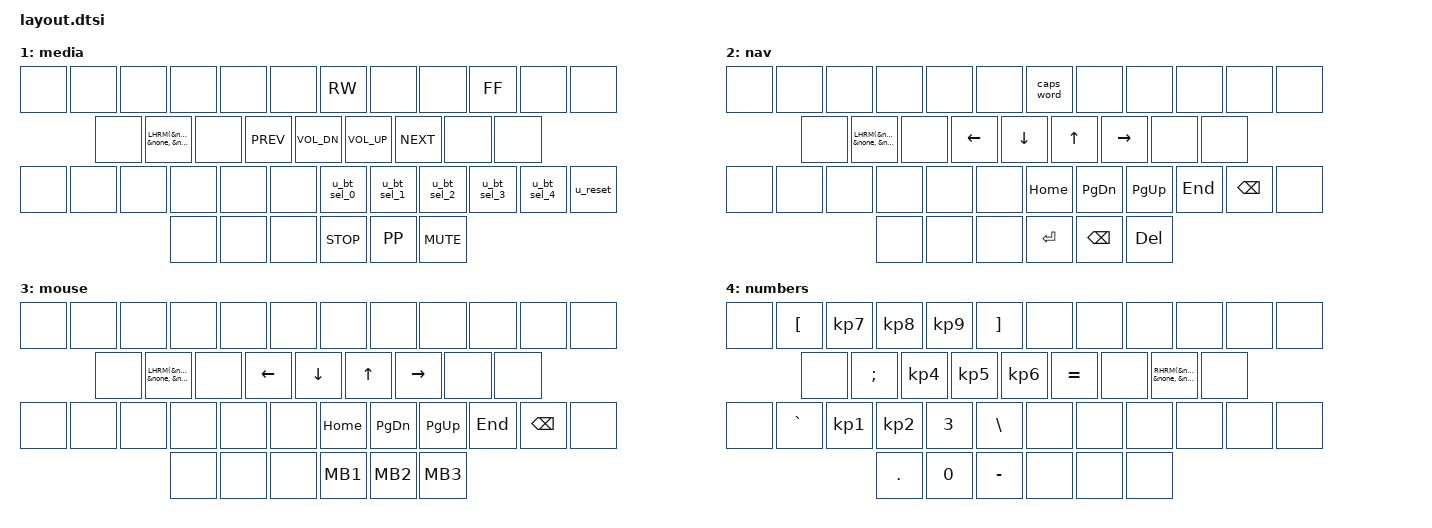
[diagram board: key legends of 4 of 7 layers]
// #include <behaviors.dtsi>
#include <dt-bindings/zmk/keys.h>
#include <dt-bindings/zmk/bt.h>
#include <dt-bindings/zmk/outputs.h>
#include <dt-bindings/zmk/ext_power.h>

#include "layout.h"

#include "mouse.dtsi"
#include "shift_functions.dtsi"

#define LHRM(k1, k2, k3, k4) &lhmr LGUI k1 &lhmr LALT k2 &lhmr LCTRL k3 &lhmr LSHIFT k4
#define RHRM(k1, k2, k3, k4) &rhmr RGUI k4 &rhmr RALT k3 &rhmr RCTRL k2 &rhmr RSHIFT k1

#define BASE 0
#define MEDIA 1
#define NAV 2
#define MOUSE 3
#define NUM 4
#define SYM 5
#define FUNC 6

&caps_word {
  continue-list = <UNDERSCORE MINUS>;
};

// #if defined(NICE_VIEW_SPI)
// &nice_view_spi {
//   cs-gpios = <NICE_VIEW_SPI>;
// };
// #endif

/
{
  keymap {
    compatible = "zmk,keymap";

    // behaviors {
    //   rhmr:
    //     rhmr {
    //       compatible = "zmk,behavior-hold-tap";
    //       bindings = <&kp>, <&kp>;
    //
    //       #binding-cells = < 2>;
    //       tapping-term-ms = <300>;
    //       quick-tap-ms = <250>;
    //       flavor = "tap-preferred";
    //       require-prior-idle-ms = <150>;
    //       hold-trigger-key-positions = <0 1 2 3 4 5 12 13 14 15 16 17 24 25 26 27 28 29 36 37 38 39 40 41>;
    //     };
    //
    //   lhmr:
    //     lhmr {
    //       compatible = "zmk,behavior-hold-tap";
    //       bindings = <&kp>, <&kp>;
    //
    //       #binding-cells = < 2>;
    //       tapping-term-ms = <300>;
    //       quick-tap-ms = <250>;
    //       flavor = "tap-preferred";
    //       require-prior-idle-ms = <150>;
    //       hold-trigger-key-positions = <6 7 8 9 10 11 18 19 20 21 22 23 30 31 32 33 34 35 36 37 38 39 40 41>;
    //     };
    // };

    base {
      // ╭──────────┬──────────┬──────────┬──────────┬───────────┬──────────╮       ╭──────────┬───────────┬──────────┬──────────┬──────────┬──────────╮
      // │          │  Q       │  W       │  E       │  R        │  T       │       │  Y       │  U        │  I       │  O       │  P       │          │
      // ├──────────┼──────────┼──────────┼──────────┼───────────┼──────────┤       ├──────────┼───────────┼──────────┼──────────┼──────────┼──────────┤
      // │          │  A       │  S       │  D       │  F        │  G       │       │  H       │  J        │  K       │  L       │  '       │          │
      // ├──────────┼──────────┼──────────┼──────────┼───────────┼──────────┤       ├──────────┼───────────┼──────────┼──────────┼──────────┼──────────┤
      // │          │  Z       │  X       │  C       │  V        │  B       │       │  N       │  M        │  ,       │  .       │  /       │          │
      // ╰──────────┴──────────┼──────────┴─────┬────┴────────┬──┴──────────┤       ├──────────┴──┬────────┴────┬─────┴───────┬──┴──────────┴──────────╯
      //                       │  ESC           │ SPACE       │ TAB         │       │  ENTER      │  BCKSPC     │  DELETE     │
      //                       ╰────────────────┴─────────────┴─────────────╯       ╰─────────────┴─────────────┴─────────────╯
      bindings = <&none &kp Q &kp W &kp E &kp R &kp T &kp Y &kp U &kp I &kp O &kp P &none

                  &none LHRM(A, S, D, F) &kp G &kp H RHRM(J, K, L, SINGLE_QUOTE) &none

                  &none &kp Z &kp X &kp C &kp V &kp B &kp N &kp M &kp COMMA &kp DOT &kp FSLH &none

                  &lt MEDIA ESC &lt NAV SPACE &lt MOUSE TAB &lt NUM RET &lt SYM BSPC &lt FUNC DEL>;
    };

    media {
      // ╭──────────┬──────────┬──────────┬──────────┬───────────┬──────────╮       ╭──────────┬───────────┬──────────┬──────────┬──────────┬──────────╮
      // │          │          │          │          │           │          │       │          │           │          │          │          │          │
      // ├──────────┼──────────┼──────────┼──────────┼───────────┼──────────┤       ├──────────┼───────────┼──────────┼──────────┼──────────┼──────────┤
      // │          │          │          │          │           │          │       │          │           │          │          │          │          │
      // ├──────────┼──────────┼──────────┼──────────┼───────────┼──────────┤       ├──────────┼───────────┼──────────┼──────────┼──────────┼──────────┤
      // │          │          │          │          │           │          │       │          │           │          │          │          │          │
      // ╰──────────┴──────────┼──────────┴─────┬────┴────────┬──┴──────────┤       ├──────────┴──┬────────┴────┬─────┴───────┬──┴──────────┴──────────╯
      //                       │                │             │             │       │             │             │             │
      //                       ╰────────────────┴─────────────┴─────────────╯       ╰─────────────┴─────────────┴─────────────╯
      bindings = <&none &none &none &none &none &none &kp C_RW &none &none &kp C_FF &none &none

                  &none LHRM(&none, &none, &none, &none) &none &kp K_PREV &kp C_VOL_DN &kp C_VOL_UP &kp K_NEXT &none &none

                  &none &none &none &none &none &none &u_bt_sel_0 &u_bt_sel_1 &u_bt_sel_2 &u_bt_sel_3 &u_bt_sel_4 &u_reset

                  &none &none &none &kp K_STOP &kp K_PP &kp C_MUTE>;
    };

    nav {
      // ╭──────────┬──────────┬──────────┬──────────┬───────────┬──────────╮       ╭──────────┬───────────┬──────────┬──────────┬──────────┬──────────╮
      // │          │          │          │          │           │          │       │ PScreen  │           │          │          │          │          │
      // ├──────────┼──────────┼──────────┼──────────┼───────────┼──────────┤       ├──────────┼───────────┼──────────┼──────────┼──────────┼──────────┤
      // │          │  GUI     │  ALT     │  CTRL    │  SHIFT    │          │       │ Left     │ Down      │ Up       │ Right    │          │          │
      // ├──────────┼──────────┼──────────┼──────────┼───────────┼──────────┤       ├──────────┼───────────┼──────────┼──────────┼──────────┼──────────┤
      // │          │          │          │          │           │          │       │ Home     │ Page down │ Page up  │ End      │          │          │
      // ╰──────────┴──────────┼──────────┴─────┬────┴────────┬──┴──────────┤       ├──────────┴──┬────────┴────┬─────┴───────┬──┴──────────┴──────────╯
      //                       │                │             │             │       │ ENTER       │ BCKSPC      │ DELETE      │
      //                       ╰────────────────┴─────────────┴─────────────╯       ╰─────────────┴─────────────┴─────────────╯
      bindings = <&none &none &none &none &none &none &caps_word &none &none &none &none &none

                  &none LHRM(&none, &none, &none, &none) &none &kp LEFT &kp DOWN &kp UP &kp RIGHT &none &none

                  &none &none &none &none &none &none &kp HOME &kp PG_DN &kp PG_UP &kp END &kp BSPC &none

                  &none &none &none &kp RET &kp BSPC &kp DEL>;
    };

    mouse {
      // ╭──────────┬──────────┬──────────┬──────────┬───────────┬──────────╮       ╭──────────┬───────────┬──────────┬──────────┬──────────┬──────────╮
      // │          │          │          │          │           │          │       │ PScreen  │           │          │          │          │          │
      // ├──────────┼──────────┼──────────┼──────────┼───────────┼──────────┤       ├──────────┼───────────┼──────────┼──────────┼──────────┼──────────┤
      // │          │  GUI     │  ALT     │  CTRL    │  SHIFT    │          │       │ M. Left  │ M. Down   │ M. Up    │ M. Right │          │          │
      // ├──────────┼──────────┼──────────┼──────────┼───────────┼──────────┤       ├──────────┼───────────┼──────────┼──────────┼──────────┼──────────┤
      // │          │          │          │          │           │          │       │ Home     │ Page down │ Page up  │ End      │          │          │
      // ╰──────────┴──────────┼──────────┴─────┬────┴────────┬──┴──────────┤       ├──────────┴──┬────────┴────┬─────┴───────┬──┴──────────┴──────────╯
      //                       │                │             │             │       │  ENTER      │  BCKSPC     │  DELETE     │
      //                       ╰────────────────┴─────────────┴─────────────╯       ╰─────────────┴─────────────┴─────────────╯
      bindings = <&none &none &none &none &none &none &none &none &none &none &none &none

                  // &none LHRM(&none, &none, &none, &none) &none U_MS_L U_MS_D U_MS_U U_MS_R &none &none
                  &none LHRM(&none, &none, &none, &none) &none &kp LEFT &kp DOWN &kp UP &kp RIGHT &none &none

                  &none &none &none &none &none &none &kp HOME &kp PG_DN &kp PG_UP &kp END &kp BSPC &none

                  &none &none &none &kp MB1 &kp MB2 &kp MB3>;
    };

    numbers {
      // ╭──────────┬──────────┬──────────┬──────────┬───────────┬──────────╮       ╭──────────┬───────────┬──────────┬──────────┬──────────┬──────────╮
      // │          │  [       │  7       │  8       │  9        │  ]       │       │          │           │          │          │          │          │
      // ├──────────┼──────────┼──────────┼──────────┼───────────┼──────────┤       ├──────────┼───────────┼──────────┼──────────┼──────────┼──────────┤
      // │          │  ;       │  4       │  5       │  6        │  =       │       │          │           │          │          │          │          │
      // ├──────────┼──────────┼──────────┼──────────┼───────────┼──────────┤       ├──────────┼───────────┼──────────┼──────────┼──────────┼──────────┤
      // │          │  `       │  1       │  2       │  3        │  \       │       │          │           │          │          │          │          │
      // ╰──────────┴──────────┼──────────┴─────┬────┴────────┬──┴──────────┤       ├──────────┴──┬────────┴────┬─────┴───────┬──┴──────────┴──────────╯
      //                       │  .             │  0          │  -          │       │             │             │             │
      //                       ╰────────────────┴─────────────┴─────────────╯       ╰─────────────┴─────────────┴─────────────╯
      bindings = <&none &kp LBKT &kp KP_N7 &kp KP_N8 &kp KP_N9 &kp RBKT &none &none &none &none &none &none

                  &none &kp SEMI &kp KP_N4 &kp KP_N5 &kp KP_N6 &kp EQUAL &none RHRM(&none, &none, &none, &none) &none

                  &none &kp GRAVE &kp KP_N1 &kp KP_N2 &kp N3 &kp BSLH &none &none &none &none &none &none

                  &kp DOT &kp N0 &kp MINUS &none &none &none>;
    };

    symbols {
      // ╭──────────┬──────────┬──────────┬──────────┬───────────┬──────────╮       ╭──────────┬───────────┬──────────┬──────────┬──────────┬──────────╮
      // │          │  {       │  &       │  *       │  (        │  }       │       │          │           │          │          │          │          │
      // ├──────────┼──────────┼──────────┼──────────┼───────────┼──────────┤       ├──────────┼───────────┼──────────┼──────────┼──────────┼──────────┤
      // │          │  :       │  $       │  %       │  ^        │  +       │       │          │           │          │          │          │          │
      // ├──────────┼──────────┼──────────┼──────────┼───────────┼──────────┤       ├──────────┼───────────┼──────────┼──────────┼──────────┼──────────┤
      // │          │  ~       │  !       │  @       │  #        │  \       │       │          │           │          │          │          │          │
      // ╰──────────┴──────────┴──┬───────┴─────┬────┴────────┬──┴──────────┤       ├──────────┴──┬────────┴────┬─────┴───────┬──┴──────────┴──────────╯
      //                          │  (          │  )          │  _          │       │             │             │             │
      //                          ╰─────────────┴─────────────┴─────────────╯       ╰─────────────┴─────────────┴─────────────╯
      bindings = <&none &kp LBRC &kp AMPS &kp STAR &kp LPAR &kp RBRC &none &none &none &none &none &none

                  &none &kp COLON &kp DOLLAR &kp PRCNT &kp CARET &kp PLUS &none &none &none &none &none &none

                  &none &kp TILDE &kp EXCL &kp AT &kp HASH &kp BSLH &none &none &none &none &none &none

                  &kp LPAR &kp RPAR &kp UNDERSCORE &none &none &none>;
    };

    function {
      // ╭──────────┬──────────┬──────────┬──────────┬───────────┬──────────╮       ╭──────────┬───────────┬──────────┬──────────┬──────────┬──────────╮
      // │          │  F12     │  F7      │  F8      │  F9       │  PSCRN   │       │          │           │          │          │          │          │
      // ├──────────┼──────────┼──────────┼──────────┼───────────┼──────────┤       ├──────────┼───────────┼──────────┼──────────┼──────────┼──────────┤
      // │          │  F11     │  F4      │  F5      │  F6       │          │       │          │           │          │          │          │          │
      // ├──────────┼──────────┼──────────┼──────────┼───────────┼──────────┤       ├──────────┼───────────┼──────────┼──────────┼──────────┼──────────┤
      // │          │  F10     │  F1      │  F2      │  F3       │          │       │          │           │          │          │          │          │
      // ╰──────────┴──────────┼──────────┴─────┬────┴────────┬──┴──────────┤       ├──────────┴──┬────────┴────┬─────┴───────┬──┴──────────┴──────────╯
      //                       │  Repeat        │  Space      │  Menu       │       │             │             │             │
      //                       ╰────────────────┴─────────────┴─────────────╯       ╰─────────────┴─────────────┴─────────────╯
      bindings = <&none &kp F12 &kp F7 &kp F8 &kp F9 &kp PSCRN &none &none &none &none &none

                  &none &kp F11 &kp F4 &kp F5 &kp F6 &none &none RHRM(&none, &none, &none, &none) &none

                  &none &kp F10 &kp F1 &kp F2 &kp F3 &none &none &none &none &none &none &none

                  &key_repeat &kp SPACE &kp K_APP &none &none &none>;
    };
  };
};
